# EFR32FG23B021F512IM48 register map
Vendor: Silicon Labs; Series: EFR32; File version: C
CPU: CM33 r0p4, little endian, MPU, FPU, DSP, VTOR, 4 interrupt priority bits, 8 SAU regions
Registers are 32-bit, read-write, reset 0x0 unless marked. A register's access mark holds for its fields unless they carry their own. Offsets are from the block's base; [hi:lo] are bit positions; {n}, {i} and the like mark numbered series.

## ACMP0_NS — ACMP0_NS Registers
Base 0x59008000
Same registers: ACMP0_S 0x49008000, ACMP1_S 0x4900C000, ACMP1_NS 0x5900C000
0x00 IPVERSION ro reset 0x1
  [31:0] IPVERSION — IP version ID
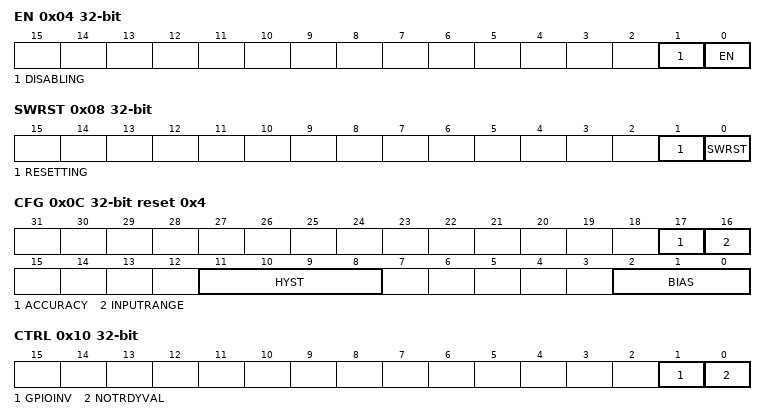
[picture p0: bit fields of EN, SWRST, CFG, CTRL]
0x04 EN
  [1] DISABLING ro — Disablement busy status
  [0] EN — Module enable
0x08 SWRST
  [1] RESETTING ro — Software reset busy status
  [0] SWRST wo — Software reset
0x0C CFG reset 0x4
  [17] ACCURACY — ACMP accuracy mode
    0=LOW (ACMP operates in low-accuracy mode but consumes less current.); 1=HIGH (ACMP operates in high-accuracy mode but consumes more current.)
  [16] INPUTRANGE
    0=FULL (Use this setting when the input to the comparator core can be from 0 to AVDD.); 1=REDUCED (It is recommended to use this setting when the input to the comparator core will always be less than AVDD-0.7V.)
  [11:8] HYST — Hysteresis mode
    0=DISABLED (Hysteresis disabled); 1=SYM10MV (10mV symmetrical hysteresis); 2=SYM20MV (20mV symmetrical hysteresis); 3=SYM30MV (30mV symmetrical hysteresis); 4=POS10MV (10mV hysteresis on positive edge transitions); 5=POS20MV (20mV hysteresis on positive edge transitions); 6=POS30MV (30mV hysteresis on positive edge transitions); 8=NEG10MV (10mV hysteresis on negative edge transitions); 9=NEG20MV (20mV hysteresis on negative edge transitions); 10=NEG30MV (30mV hysteresis on negative edge transitions)
  [2:0] BIAS — Bias Configuration
0x10 CTRL
  [1] GPIOINV — Comparator GPIO Output Invert
    0=NOTINV (The comparator output to GPIO is not inverted); 1=INV (The comparator output to GPIO is inverted)
  [0] NOTRDYVAL — Not Ready Value
    0=LOW (ACMP output is 0 when the ACMP is not ready.); 1=HIGH (ACMP output is 1 when the ACMP is not ready.)
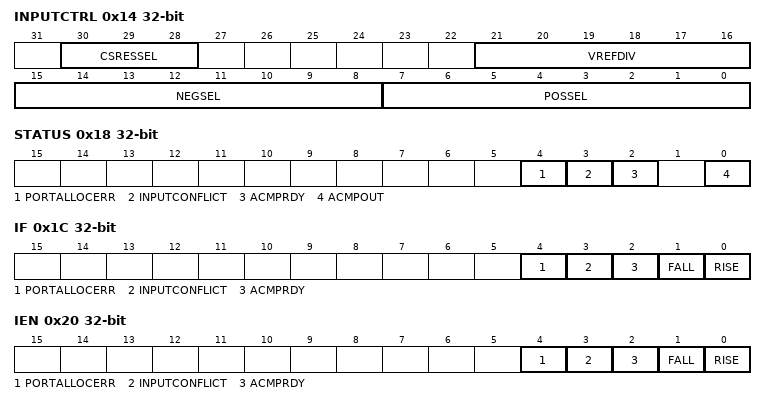
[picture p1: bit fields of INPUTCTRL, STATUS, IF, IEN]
0x14 INPUTCTRL
  [30:28] CSRESSEL — Capacitive Sense Mode Internal Resistor
    {v}=RES{v} (Internal capacitive sense resistor value {v}) (v=0..6)
  [21:16] VREFDIV — VREF division
  [15:8] NEGSEL — Negative Input Select
    0=VSS; 16=VREFDIVAVDD (Divided AVDD); 17=VREFDIVAVDDLP (Low-Power Divided AVDD); 18=VREFDIV1V25 (Divided 1V25 reference); 19=VREFDIV1V25LP (Low-power Divided 1V25 reference); 20=VREFDIV2V5 (Divided 2V5 reference); 21=VREFDIV2V5LP (Low-power Divided 2V5 reference); 32=VSENSE01DIV4 (VSENSE0 divided by 4); 33=VSENSE01DIV4LP (Low-power VSENSE0 divided by 4); 34=VSENSE11DIV4 (VSENSE1 divided by 4); 35=VSENSE11DIV4LP (Low-power VSENSE1 divided by 4); 48=CAPSENSE (Deprecated capacitive sensing feature, not recommended for new designs); 64=VDACOUT0 (VDAC0 channel 0 output); 65=VDACOUT1 (VDAC0 channel 1 output); {v}=PA{v-128} (Port A, Pin{v-128}) (v=128..143); {v}=PB{v-144} (Port B, Pin{v-144}) (v=144..159); {v}=PC{v-160} (Port C, Pin{v-160}) (v=160..175); {v}=PD{v-176} (Port D, Pin{v-176}) (v=176..191)
  [7:0] POSSEL — Positive Input Select
    0=VSS; 16=VREFDIVAVDD (Divided AVDD); 17=VREFDIVAVDDLP (Low-Power Divided AVDD); 18=VREFDIV1V25 (Divided 1V25 reference); 19=VREFDIV1V25LP (Low-power Divided 1V25 reference); 20=VREFDIV2V5 (Divided 2V5 reference); 21=VREFDIV2V5LP (Low-power Divided 2V5 reference); 32=VSENSE01DIV4 (VSENSE0 divided by 4); 33=VSENSE01DIV4LP (Low-power VSENSE0 divided by 4); 34=VSENSE11DIV4 (VSENSE1 divided by 4); 35=VSENSE11DIV4LP (Low-power VSENSE1 divided by 4); 64=VDACOUT0 (VDAC0 channel 0 output); 65=VDACOUT1 (VDAC0 channel 1 output); 80=EXTPA (External interface, base is PA0.); 81=EXTPB (External interface, base is PB0.); 82=EXTPC (External interface, base is PC0.); 83=EXTPD (External interface, base is PD0.); {v}=PA{v-128} (Port A, Pin{v-128}) (v=128..143); {v}=PB{v-144} (Port B, Pin{v-144}) (v=144..159); {v}=PC{v-160} (Port C, Pin{v-160}) (v=160..175); {v}=PD{v-176} (Port D, Pin{v-176}) (v=176..191)
0x18 STATUS ro
  [4] PORTALLOCERR — Port allocation error
  [3] INPUTCONFLICT
  [2] ACMPRDY — Analog Comparator Ready
  [0] ACMPOUT — Analog Comparator Output
0x1C IF
  [4] PORTALLOCERR — Port allocation error
  [3] INPUTCONFLICT
  [2] ACMPRDY — ACMP ready Interrupt flag
  [1] FALL — Falling Edge Triggered Interrupt Flag
  [0] RISE — Rising Edge Triggered Interrupt Flag
0x20 IEN
  [4] PORTALLOCERR — Port allocation error interrupt enable
  [3] INPUTCONFLICT — Input conflict interrupt enable
  [2] ACMPRDY — ACMP ready interrupt enable
  [1] FALL — Falling edge interrupt enable
  [0] RISE — Rising edge interrupt enable
0x24 SYNCBUSY ro
  [0] INPUTCTRL — Syncbusy for INPUTCTRL
